# STM32H7P5 register map
File version: 0.1
CPU: CM7 r1p2, little endian, MPU, FPU, 4 interrupt priority bits
Registers are 32-bit, read-write, reset 0x0 unless marked. A register's access mark holds for its fields unless they carry their own. Offsets are from the block's base; [hi:lo] are bit positions; {n}, {i} and the like mark numbered series; 'fields as' and 'values as' point back to an identical list.

## IWDG — IWDG register block
Base 0x58004800
0x00 IWDG_KR wo — IWDG key register
  [15:0] KEY — Key value (write only, read 0x0000)
0x04 IWDG_PR — IWDG prescaler register
  [3:0] PR — Prescaler divider
    0=divider / 4; 1=divider / 8; 2=divider / 16; 3=divider / 32; 4=divider / 64; 5=divider / 128; 6=divider / 256; 7=divider / 512
0x08 IWDG_RLR reset 0xFFF — IWDG reload register
  [11:0] RL — Watchdog counter reload value
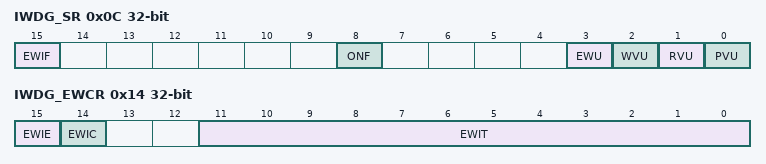
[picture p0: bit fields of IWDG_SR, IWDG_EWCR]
0x0C IWDG_SR ro — IWDG status register
  [15] EWIF — Watchdog early interrupt flag
  [8] ONF — Watchdog enable status bit
    0=The IWDG is not activated; 1=The IWDG is activated and needs to be refreshed regularly by the application
  [3] EWU — Watchdog interrupt comparator value update
  [2] WVU — Watchdog counter window value update
  [1] RVU — Watchdog counter reload value update
  [0] PVU — Watchdog prescaler value update
0x10 IWDG_WINR reset 0xFFF — IWDG window register
  [11:0] WIN — Watchdog counter window value
0x14 IWDG_EWCR — IWDG early wake-up interrupt register
  [15] EWIE — Watchdog early interrupt enable
    0=The early interrupt interface is disabled; 1=The early interrupt interface is enabled
  [14] EWIC wo — Watchdog early interrupt acknowledge
  [11:0] EWIT — Watchdog counter window value

## RAMECC1 — RAMECC address block description
Base 0x52009000
Same registers: RAMECC2 0x58027000
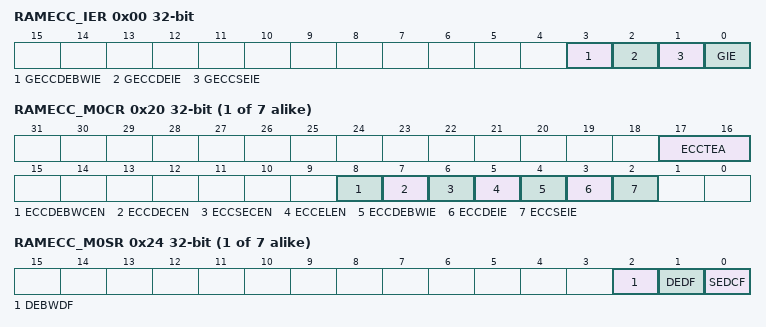
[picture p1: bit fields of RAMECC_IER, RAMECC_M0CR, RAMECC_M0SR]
0x00 RAMECC_IER — RAMECC interrupt enable register
  [3] GECCDEBWIE — Global ECC double error on byte write (BW) interrupt enable
    0=no interrupt generated when an ECC double detection error occurs on byte write; 1=interrupt generated if an ECC double detection error occurs on byte write
  [2] GECCDEIE — Global ECC double error interrupt enable
    0=no interrupt generated when an ECC double detection error occurs; 1=interrupt generated if an ECC double detection error occurs
  [1] GECCSEIE — Global ECC single error interrupt enable
    0=no interrupt generated when an ECC single error occurs; 1=interrupt generated when an ECC single error occurs
  [0] GIE — Global interrupt enable
    0=no interrupt generated when an ECC error occurs; 1=interrupt generated when an ECC error occurs
{0x20+0x20*i} RAMECC_M{i}CR (i=0..6) — RAMECC monitor {i} configuration register
  [17:16] ECCTEA — ECC Test ECC access
    0=inactive; 1=write and read access blocked on data memory; 2=write and read access blocked on ECC memory; 3=inactive
  [8] ECCDEBWCEN — ECC double error on byte write (BW) counter enable
    0=no counter increment when an ECC double detection error occurs on byte write; 1=counter increment when an ECC double detection error occurs on byte write
  [7] ECCDECEN — ECC double error counter enable
    0=no counter increment when an ECC double detection error occurs; 1=counter increment when an ECC double detection error occurs
  [6] ECCSECEN — ECC single error counter enable
    0=no counter increment when an ECC single error occurs; 1=counter increment when an ECC single error occurs
  [5] ECCELEN — ECC error latching enable
    0=no error context preserved when an ECC error occurs; 1=error context preserved when an ECC error occurs
  [4] ECCDEBWIE — ECC double error on byte write (BW) interrupt enable
    values as RAMECC_IER.GECCDEBWIE
  [3] ECCDEIE — ECC double error interrupt enable
    values as RAMECC_IER.GECCDEIE
  [2] ECCSEIE — ECC single error interrupt enable
    values as RAMECC_IER.GECCSEIE
{0x24+0x20*i} RAMECC_M{i}SR (i=0..6) — RAMECC monitor {i} status register
  [2] DEBWDF — ECC double error on byte write (BW) detected flag
    0=no error detected; 1=error detected
  [1] DEDF — ECC double error detected flag
    0=no error detected; 1=error detected
  [0] SEDCF — ECC single error detected and corrected flag
    0=no error detected and corrected; 1=error detected and corrected
{0x28+0x20*i} RAMECC_M{i}FAR ro (i=0..6) — RAMECC monitor {i} failing address register
  [31:0] FADD — ECC error failing address
{0x2C+0x20*i} RAMECC_M{i}FDRL ro (i=0..6) — RAMECC monitor {i} failing data low register
  [31:0] FDATAL — Failing data low
{0x30+0x20*i} RAMECC_M{i}FDRH ro (i=0..6) — RAMECC monitor {i} failing data high register
  [31:0] FDATAH — Failing data high (64-bit memory)
{0x34+0x20*i} RAMECC_M{i}FECR ro (i=0..6) — RAMECC monitor {i} failing ECC error code register
  [31:0] FEC — Failing error code
